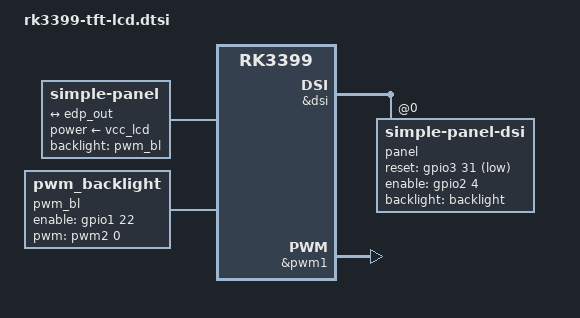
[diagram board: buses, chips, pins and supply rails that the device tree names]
/*
 *粗劣关于rk3399使用显示屏的设备树
 *10.1寸屏使用MIPI借口，双屏控制器vopb和vopl目前不确定使用哪个,因此后续代码需要对应修改
 *edp设置位于rk3399.dtsi第2099行
 *dsi设置位于rk3399.dtsi第2033行
 *display_subsystem位于rk3399-android.dtsi第315行
 *后续会移植到rk3399-sapphire-excavator-edp.dts然后进行相应的修改
 */


#include "rk3399.dtsi"
#include "rk3399-android.dtsi"
//edp屏
&edp {
	status = "okay";
	// Embedded Connection不需要HPD功能
	force-hpd;
	
	ports {
		// 输出Port1，连接panel的输入
		port@1 {
			reg = <1>;
			
			edp_out: endpoint {
				remote-endpoint = <&edp_panel>;
			};
		};
	};
};
&edp_in_vopb {
	status = "okay";
};
edp_in_vopl {
	status = "disabled";
};

&route_edp {
	status = "okay";
	logo,mode = "center";
	connect = <&vopb_out_edp>;
};

// edp面板
panel: edp-panel {
	status = "okay";
	compatible = "simple-panel";

	backlight = <&pwm_bl>;
	power-supply = <&vcc_lcd>;
	prepare-delay-ms = <20>;
	enable-delay-ms = <20>;
	
	// timings设置，可通过设备树中配置/驱动中配置/EDID三种方式实现
	dispaly-timings {
		native-mode = <&edp_timing>;
		
		// hsync start = hactive + hfront-porch
        // hsync end = hactive + hfront-porch + hsync-len
        // htotal = hactive + hfront-porch + hsync‐len + hback-porch
		edp_timing: timing0 {
			clock-frequency = <138500000>;
			hactive = <1920>;
			vactive = <1080>;
			hfront-porch = <64>;
			hsync-len = <48>;
			hback-porch = <48>;
			vfront-porch = <3>;
			vsync-len = <6>;
			vback-porch = <3>;
			hsync-active = <0>;
			vsync-active = <0>;
			de-active = <0>;
			pixelclk-active = <0>;
		};
	};

	ports {
		edp_panel: endpoint {
			remote-endpoint = <&edp_out>;
			};
	};
};

// pwm背光配置
// 使用命令行设置背光亮度:
// echo xxx > sys/class/backlight/backlight/brightness

pwm_bl: backlight {
	status = "okay";
	compatible = "pwm_backlight";
	// pwm0表示选择pwm0；0表示index，一般为0；25000表示PWM输出波形的时间
    // 周期，单位为ns；0表示极性
	pwms = <&pwm2 0 25000 0>;
	// 0~255表示0%~100%
	brightness-levels = <
		0 1 2 3 4 5 6 7
		8 9 10 11 12 13 14 15
		16 17 18 19 20 21 22 23
		24 25 26 27 28 29 30 31
		32 33 34 35 36 37 38 39
		40 41 42 43 44 45 46 47
		48 49 50 51 52 53 54 55
		56 57 58 59 60 61 62 63
		64 65 66 67 68 69 70 71
		72 73 74 75 76 77 78 79
		80 81 82 83 84 85 86 87
		88 89 90 91 92 93 94 95
		96 97 98 99 100 101 102 103
		104 105 106 107 108 109 110 111
		112 113 114 115 116 117 118 119
		120 121 122 123 124 125 126 127
		128 129 130 131 132 133 134 135
		136 137 138 139 140 141 142 143
		144 145 146 147 148 149 150 151
		152 153 154 155 156 157 158 159
		160 161 162 163 164 165 166 167
		168 169 170 171 172 173 174 175
		176 177 178 179 180 181 182 183
		184 185 186 187 188 189 190 191
		192 193 194 195 196 197 198 199
		200 201 202 203 204 205 206 207
		208 209 210 211 212 213 214 215
		216 217 218 219 220 221 222 223
		224 225 226 227 228 229 230 231
		232 233 234 235 236 237 238 239
		240 241 242 243 244 245 246 247
		248 249 250 251 252 253 254 255>;
	default-brightness-level = <200>;
	enable-gpios = <&gpio1 22 GPIO_ACTIVE_HIGH>;
};

//MIPI屏配置
&dsi {
	status = "okay";
	
	panel@0 {
		compatible = "simple-panel-dsi";
		reg = <0>;
		backlight = <&backlight>;
		reset-gpios = <&gpio3 31 GPIO_ACTIVE_LOW>; //待定
		enable-gpios = <&gpio2 4 GPIO_ACTIVE_HIGH>;//待定
		prepare-delay-ms = <10>;
		reset-delay-ms = <5>;
		init-delay-ms = <50>;
		enable-delay-ms = <50>;
		
		dsi,flags = <(MIPI_DSI_MODE_VIDEO | MIPI_DSI_MODE_VIDEO_BURST |
		              MIPI_DSI_MODE_LPM | MIPI_DSI_MODE_EOT_PACKET)>;
		//dsi数据格式
		dsi,format = <MIPI_DSI_FMT_RGB888>;
		// MIPI接口使用的lane数量，需要与硬件匹配
		dsi,lanes = <4>;
		
		//初始化序列，需找厂商要
		panel-init-sequence = [
		//待定
		];
		
		//退出序列，需找厂商要
		panel-exit-sequence =  [
			05 78 01 28
			05 00 01 10 //待定
		];
		
		//屏参数设置
		display-timings {
			native-mode = <&tft_lcd_timing>;
			
			tft_lcd_timing: timing0 {
				// 像素时钟频率（每个像素显示1s需要的时钟频率 fps为60）
				// (h_active + hfp + hbp + h_sync) * (v_active + vfp + vbp + v_sync) * fps
			clock-frequency = <67330000>;    //待定
			hactive = <800>;
			vactive = <1280>;
			hfront-porch = <18>;
			hsync-len = <18>;  //待定
			hback-porch = <18>;
			vfront-porch = <20>;
			vsync-len = <4>;   //待定
			vback-porch = <10>;
			hsync-active = <0>;
			vsync-active = <0>;
			de-active = <0>;
			pixelclk-active = <0>;
			};
		};				
	};
};

&backlight {
	status = "okay";
	pwms = <&pwm1 0 25000 0>; //待定
	enable-gpios = <&gpio1 4 GPIO_ACTIVE_HIGH>; //待定
};

&pwm1 {   //对应上面backlight里面的pwm1
	status = "okay";
};

&dsi_in_vopb {
	status = "disabled";
};

&dsi_in_vopl {
	status = "okay";
};

&route_dsi {
	status = "okay";
	connect = <&vopl_out_dsi>;
};



